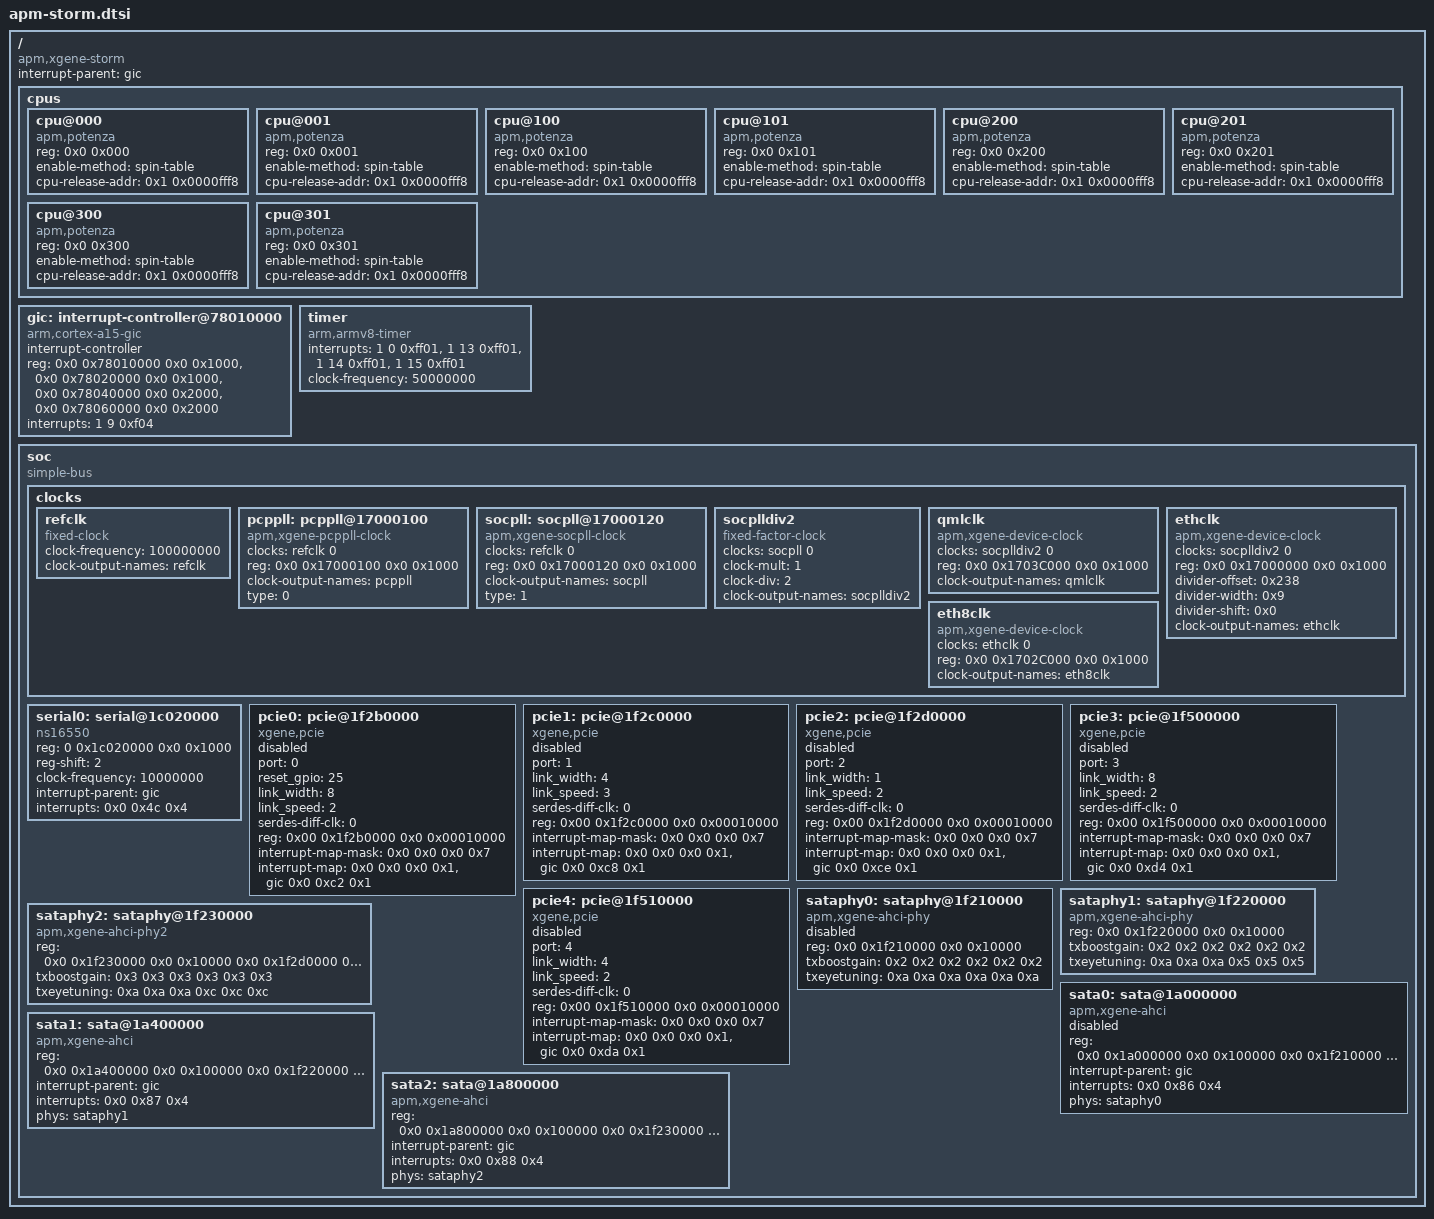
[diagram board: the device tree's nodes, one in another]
/*
 * dts file for AppliedMicro (APM) X-Gene Storm SOC
 *
 * Copyright (C) 2013, Applied Micro Circuits Corporation
 *
 * This program is free software; you can redistribute it and/or
 * modify it under the terms of the GNU General Public License as
 * published by the Free Software Foundation; either version 2 of
 * the License, or (at your option) any later version.
 */

/ {
	compatible = "apm,xgene-storm";
	interrupt-parent = <&gic>;
	#address-cells = <2>;
	#size-cells = <2>;

	cpus {
		#address-cells = <2>;
		#size-cells = <0>;

		cpu@000 {
			device_type = "cpu";
			compatible = "apm,potenza", "arm,armv8";
			reg = <0x0 0x000>;
			enable-method = "spin-table";
			cpu-release-addr = <0x1 0x0000fff8>;
		};
		cpu@001 {
			device_type = "cpu";
			compatible = "apm,potenza", "arm,armv8";
			reg = <0x0 0x001>;
			enable-method = "spin-table";
			cpu-release-addr = <0x1 0x0000fff8>;
		};
		cpu@100 {
			device_type = "cpu";
			compatible = "apm,potenza", "arm,armv8";
			reg = <0x0 0x100>;
			enable-method = "spin-table";
			cpu-release-addr = <0x1 0x0000fff8>;
		};
		cpu@101 {
			device_type = "cpu";
			compatible = "apm,potenza", "arm,armv8";
			reg = <0x0 0x101>;
			enable-method = "spin-table";
			cpu-release-addr = <0x1 0x0000fff8>;
		};
		cpu@200 {
			device_type = "cpu";
			compatible = "apm,potenza", "arm,armv8";
			reg = <0x0 0x200>;
			enable-method = "spin-table";
			cpu-release-addr = <0x1 0x0000fff8>;
		};
		cpu@201 {
			device_type = "cpu";
			compatible = "apm,potenza", "arm,armv8";
			reg = <0x0 0x201>;
			enable-method = "spin-table";
			cpu-release-addr = <0x1 0x0000fff8>;
		};
		cpu@300 {
			device_type = "cpu";
			compatible = "apm,potenza", "arm,armv8";
			reg = <0x0 0x300>;
			enable-method = "spin-table";
			cpu-release-addr = <0x1 0x0000fff8>;
		};
		cpu@301 {
			device_type = "cpu";
			compatible = "apm,potenza", "arm,armv8";
			reg = <0x0 0x301>;
			enable-method = "spin-table";
			cpu-release-addr = <0x1 0x0000fff8>;
		};
	};

	gic: interrupt-controller@78010000 {
		compatible = "arm,cortex-a15-gic";
		#interrupt-cells = <3>;
		interrupt-controller;
		reg = <0x0 0x78010000 0x0 0x1000>,	/* GIC Dist */
		      <0x0 0x78020000 0x0 0x1000>,	/* GIC CPU */
		      <0x0 0x78040000 0x0 0x2000>,	/* GIC VCPU Control */
		      <0x0 0x78060000 0x0 0x2000>;	/* GIC VCPU */
		interrupts = <1 9 0xf04>;	/* GIC Maintenence IRQ */
	};

	timer {
		compatible = "arm,armv8-timer";
		interrupts = <1 0 0xff01>,	/* Secure Phys IRQ */
			     <1 13 0xff01>,	/* Non-secure Phys IRQ */
			     <1 14 0xff01>,	/* Virt IRQ */
			     <1 15 0xff01>;	/* Hyp IRQ */
		clock-frequency = <50000000>;
	};

	soc {
		compatible = "simple-bus";
		#address-cells = <2>;
		#size-cells = <2>;
		ranges;

		clocks {
			#address-cells = <2>;
			#size-cells = <2>;
			ranges;
			refclk: refclk {
				compatible = "fixed-clock";
				#clock-cells = <1>;
				clock-frequency = <100000000>;
				clock-output-names = "refclk";
			};

			pcppll: pcppll@17000100 {
				compatible = "apm,xgene-pcppll-clock";
				#clock-cells = <1>;
				clocks = <&refclk 0>;
				clock-names = "pcppll";
				reg = <0x0 0x17000100 0x0 0x1000>;
				clock-output-names = "pcppll";
				type = <0>;
			};

			socpll: socpll@17000120 {
				compatible = "apm,xgene-socpll-clock";
				#clock-cells = <1>;
				clocks = <&refclk 0>;
				clock-names = "socpll";
				reg = <0x0 0x17000120 0x0 0x1000>;
				clock-output-names = "socpll";
				type = <1>;
			};

			socplldiv2: socplldiv2  {
				compatible = "fixed-factor-clock";
				#clock-cells = <1>;
				clocks = <&socpll 0>;
				clock-names = "socplldiv2";
				clock-mult = <1>;
				clock-div = <2>;
				clock-output-names = "socplldiv2";
			};

			qmlclk: qmlclk {
				compatible = "apm,xgene-device-clock";
				#clock-cells = <1>;
				clocks = <&socplldiv2 0>;
				clock-names = "qmlclk";
				reg = <0x0 0x1703C000 0x0 0x1000>;
				reg-names = "csr-reg";
				clock-output-names = "qmlclk";
			};

			ethclk: ethclk {
				compatible = "apm,xgene-device-clock";
				#clock-cells = <1>;
				clocks = <&socplldiv2 0>;
				clock-names = "ethclk";
				reg = <0x0 0x17000000 0x0 0x1000>;
				reg-names = "div-reg";
				divider-offset = <0x238>;
				divider-width = <0x9>;
				divider-shift = <0x0>;
				clock-output-names = "ethclk";
			};

			eth8clk: eth8clk {
				compatible = "apm,xgene-device-clock";
				#clock-cells = <1>;
				clocks = <&ethclk 0>;
				clock-names = "eth8clk";
				reg = <0x0 0x1702C000 0x0 0x1000>;
				reg-names = "csr-reg";
				clock-output-names = "eth8clk";
			};
		};

		serial0: serial@1c020000 {
			device_type = "serial";
			compatible = "ns16550";
			reg = <0 0x1c020000 0x0 0x1000>;
			reg-shift = <2>;
			clock-frequency = <10000000>; /* Updated by bootloader */
			interrupt-parent = <&gic>;
			interrupts = <0x0 0x4c 0x4>;
		};

		pcie0: pcie@1f2b0000 {
			device_type = "pci";
			compatible = "xgene,pcie";
			#interrupt-cells = <1>;
			#size-cells = <2>;
			#address-cells = <3>;
			port = <0>;
			reset_gpio = <25>;
			link_width = <8>;
			link_speed = <2>;
			serdes-diff-clk = <0>;
			status = "disabled";
			reg = < 0x00 0x1f2b0000 0x0 0x00010000>;
			ranges = <0x02000000 0x0 0x00000000 0xe0 0x00000000 0x0 0x10000000 /* mem*/
				  0x01000000 0x0 0x80000000 0xe0 0x80000000 0x0 0x00010000 /* io */
				  0x00000000 0x0 0xd0000000 0xe0 0xd0000000 0x0 0x00200000 /* cfg */
				  0x00000000 0x0 0x79000000 0x00 0x79000000 0x0 0x00800000>; /* msi */

			interrupt-map-mask = <0x0 0x0 0x0 0x7>;
			interrupt-map = <0x0 0x0 0x0 0x1 &gic 0x0 0xc2 0x1>;
		};

		pcie1: pcie@1f2c0000 {
			device_type = "pci";
			compatible = "xgene,pcie";
			#interrupt-cells = <1>;
			#size-cells = <2>;
			#address-cells = <3>;
			port = <1>;
			link_width = <4>;
			link_speed = <3>;
			serdes-diff-clk = <0>;
			status = "disabled";
			reg = <0x00 0x1f2c0000 0x0 0x00010000>;
			ranges = <0x02000000 0x0 0x00000000 0xd0 0x00000000 0x0 0x10000000 /* mem*/
				  0x01000000 0x0 0x80000000 0xd0 0x80000000 0x0 0x00010000 /* io */
				  0x00000000 0x0 0xd0000000 0xd0 0xd0000000 0x0 0x00200000 /* cfg */
				  0x00000000 0x0 0x79000000 0x00 0x79000000 0x0 0x00800000>; /* msi */
			interrupt-map-mask = <0x0 0x0 0x0 0x7>;
			interrupt-map = <0x0 0x0 0x0 0x1 &gic 0x0 0xc8 0x1>;
		};

		pcie2: pcie@1f2d0000 {
			device_type = "pci";
			compatible = "xgene,pcie";
			#interrupt-cells = <1>;
			#size-cells = <2>;
			#address-cells = <3>;
			port = <2>;
			link_width = <1>;
			link_speed = <2>;
			serdes-diff-clk = <0>;
			status = "disabled";
			reg =  <0x00 0x1f2d0000 0x0 0x00010000>;
			ranges = <0x02000000 0x0 0x00000000 0x90 0x00000000 0x0 0x10000000 /* mem*/
				  0x01000000 0x0 0x80000000 0x90 0x80000000 0x0 0x00010000 /* io */
				  0x00000000 0x0 0xd0000000 0x90 0xd0000000 0x0 0x00200000 /* cfg */
				  0x00000000 0x0 0x79000000 0x00 0x79000000 0x0 0x00800000>; /* msi */
			interrupt-map-mask = <0x0 0x0 0x0 0x7>;
			interrupt-map = <0x0 0x0 0x0 0x1 &gic 0x0 0xce 0x1>;
		};

		pcie3: pcie@1f500000 {
			device_type = "pci";
			compatible = "xgene,pcie";
			#interrupt-cells = <1>;
			#size-cells = <2>;
			#address-cells = <3>;
			port = <3>;
			link_width = <8>;
			link_speed = <2>;
			serdes-diff-clk = <0>;
			status = "disabled";
			reg = <0x00 0x1f500000 0x0 0x00010000>;
			ranges = <0x02000000 0x0 0x00000000 0xa0 0x00000000 0x0 0x10000000 /* mem*/
				  0x01000000 0x0 0x80000000 0xa0 0x80000000 0x0 0x00010000 /* io */
				  0x00000000 0x0 0xd0000000 0xa0 0xd0000000 0x0 0x00200000 /* cfg */
				  0x00000000 0x0 0x79000000 0x00 0x79000000 0x0 0x00800000>; /* msi */
			interrupt-map-mask = <0x0 0x0 0x0 0x7>;
			interrupt-map = <0x0 0x0 0x0 0x1 &gic 0x0 0xd4 0x1>;
		};

		pcie4: pcie@1f510000 {
			device_type = "pci";
			compatible = "xgene,pcie";
			#interrupt-cells = <1>;
			#size-cells = <2>;
			#address-cells = <3>;
			port = <4>;
			link_width = <4>;
			link_speed = <2>;
			serdes-diff-clk = <0>;
			status = "disabled";
			reg = <0x00 0x1f510000 0x0 0x00010000>;
			ranges = <0x02000000 0x0 0x00000000 0xc0 0x00000000 0x0 0x10000000 /* mem*/
				  0x01000000 0x0 0x80000000 0xc0 0x80000000 0x0 0x00010000 /* io */
				  0x00000000 0x0 0xd0000000 0xc0 0xd0000000 0x0 0x00200000 /* cfg */
				  0x00000000 0x0 0x79000000 0x00 0x79000000 0x0 0x00800000>; /* msi */
			interrupt-map-mask = <0x0 0x0 0x0 0x7>;
			interrupt-map = <0x0 0x0 0x0 0x1 &gic 0x0 0xda 0x1>;
		};

		sataphy0: sataphy@1f210000 {
			compatible = "apm,xgene-ahci-phy";
			reg = <0x0 0x1f210000 0x0 0x10000>;
			#phy-cells = <0>;
			status = "na";
			txboostgain = <0x2 0x2 0x2 0x2 0x2 0x2>;
			txeyetuning = <0xa 0xa 0xa 0xa 0xa 0xa>;
		};

		sataphy1: sataphy@1f220000 {
			compatible = "apm,xgene-ahci-phy";
			reg = <0x0 0x1f220000 0x0 0x10000>;
			#phy-cells = <0>;
			status = "ok";
			txboostgain = <0x2 0x2 0x2 0x2 0x2 0x2>;
			txeyetuning = <0xa 0xa 0xa 0x5 0x5 0x5>;
		};

		sataphy2: sataphy@1f230000 {
			compatible = "apm,xgene-ahci-phy2";
			reg = <0x0 0x1f230000 0x0 0x10000
			       0x0 0x1f2d0000 0x0 0x10000>;
			#phy-cells = <0>;
			status = "ok";
			txboostgain = <0x3 0x3 0x3 0x3 0x3 0x3>;
			txeyetuning = <0xa 0xa 0xa 0xc 0xc 0xc>;
		};

		sata0: sata@1a000000 {
			compatible = "apm,xgene-ahci";
			reg =  <0x0 0x1a000000 0x0 0x100000
				0x0 0x1f210000 0x0 0x10000>;
			interrupt-parent = <&gic>;
			interrupts = <0x0 0x86 0x4>;
			status = "na";
			phys = <&sataphy0>;
			phy-names = "sataphy1f210000";
		};

		sata1: sata@1a400000 {
			compatible = "apm,xgene-ahci";
			reg =  <0x0 0x1a400000 0x0 0x100000
				0x0 0x1f220000 0x0 0x10000>;
			interrupt-parent = <&gic>;
			interrupts = <0x0 0x87 0x4>;
			status = "ok";
			phys = <&sataphy1>;
			phy-names = "sataphy1f220000";
		};

		sata2: sata@1a800000 {
			compatible = "apm,xgene-ahci";
			reg =  <0x0 0x1a800000 0x0 0x100000
				0x0 0x1f230000 0x0 0x10000>;
			interrupt-parent = <&gic>;
			interrupts = <0x0 0x88 0x4>;
			status = "ok";
			phys = <&sataphy2>;
			phy-names = "sataphy1f230000";
		};
	};
};
